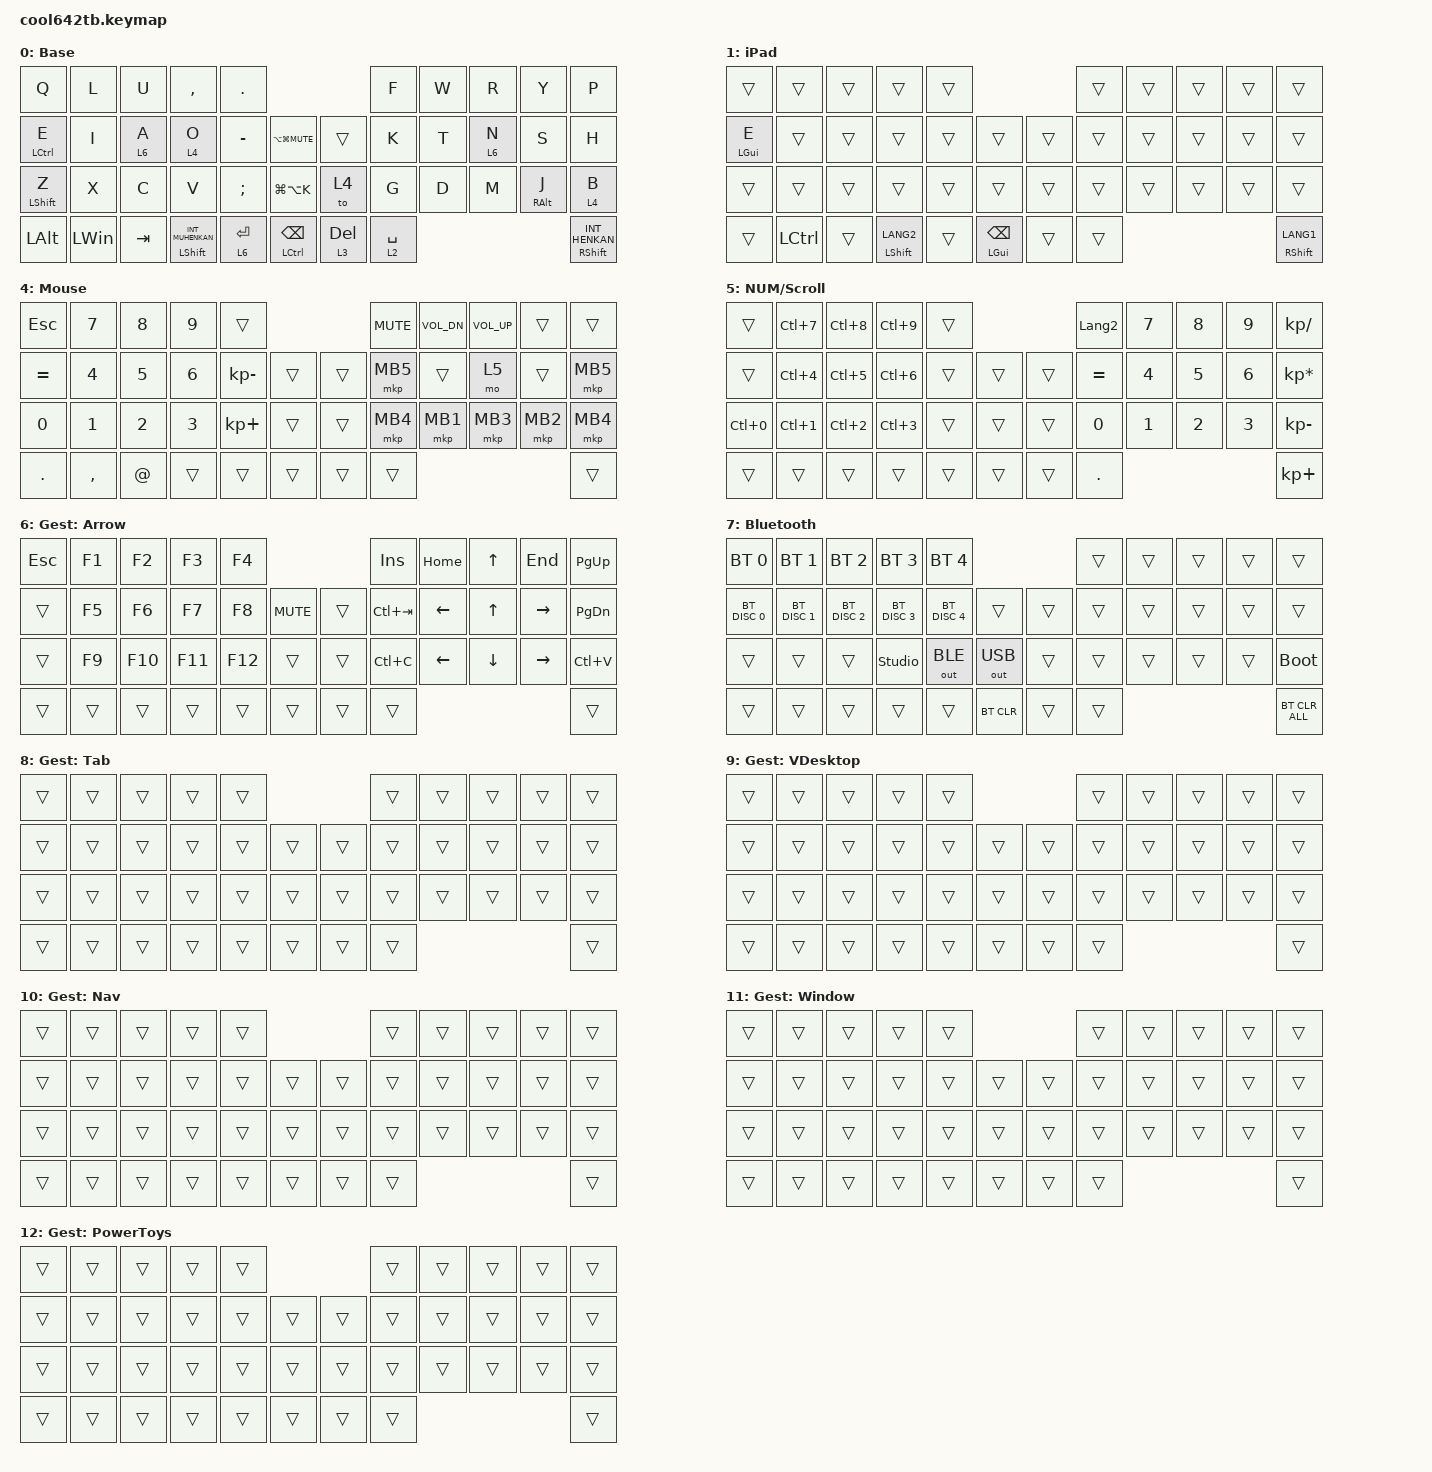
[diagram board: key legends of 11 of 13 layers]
#include <input/processors.dtsi>
#include <dt-bindings/zmk/input_transform.h>
#include <zephyr/dt-bindings/input/input-event-codes.h>

/* ── 1クリック = 1ノッチになる SCRL_VAL ──
 * &msc は押している間 trigger_period_ms (既定 16ms) ごとに
 *     move = SCRL_VAL * trigger_period_ms / 1000
 * を出力する。スムーススクロール有効時はホストが 1カウント = 1/16 ノッチと
 * 解釈するので 1000 * 0.016 = 16 カウント → 1ノッチ/クリックになる。
 * エンコーダ出力にはさらに mscbase×msclyr が掛かる (Studio で変更可)。 */

#undef ZMK_POINTING_DEFAULT_SCRL_VAL

#define ZMK_POINTING_DEFAULT_SCRL_VAL 1000

/* ランタイムマクロの &rmacro <slot> を提供。スロット番号は Studio で
 * マクロを作成したときに割り当てられる。 */

#include <behaviors/runtime_macro.dtsi>

/* &mg_set N を提供。押している間だけ RPC 側のセットが有効になる。
 * ただし Studio からは割り当てられないので、下の mg_set_0/1/2 を使う。 */

#include <mouse-gesture-rpc.dtsi>
#include <behaviors.dtsi>
#include <dt-bindings/zmk/bt.h>
#include <dt-bindings/zmk/keys.h>
#include <dt-bindings/zmk/outputs.h>
#include <dt-bindings/zmk/pointing.h>
#include "gestures.dtsi"

/* DYA Studio 用の「セット番号固定」ジェスチャーキー。
 *
 * Studio はパラメータ付きのカスタム behavior を保持できないため、汎用の
 * &mg_set N は Studio の一覧から割り当てられない。モジュール側は対策として
 * パラメータ無しの compatible "zmk,behavior-mg-set-fixed" を用意しているが、
 * ノード自体は定義していないので自前で作る。
 *
 * セット番号はノード名の末尾1文字から決まる。よってノード名は必ず
 * _0 / _1 / _2 で終わらせること。判定が '0'..'2' 固定なので3セットが上限。 */

/ {
    behaviors {
        mg_set_0: behavior_mg_set_0 {
            compatible = "zmk,behavior-mg-set-fixed";
            #binding-cells = <0>;
            display-name = "Mouse Gesture Key 0";
        };

        mg_set_1: behavior_mg_set_1 {
            compatible = "zmk,behavior-mg-set-fixed";
            #binding-cells = <0>;
            display-name = "Mouse Gesture Key 1";
        };

        mg_set_2: behavior_mg_set_2 {
            compatible = "zmk,behavior-mg-set-fixed";
            #binding-cells = <0>;
            display-name = "Mouse Gesture Key 2";
        };
    };
};

&mt {
    flavor = "tap-preferred";
    quick-tap-ms = <300>;
    require-prior-idle-ms = <125>;
    tapping-term-ms = <180>;
};

&lt {
    quick-tap-ms = <300>;
    flavor = "tap-preferred";
    require-prior-idle-ms = <125>;
    tapping-term-ms = <180>;
};

/* &msc (エンコーダのスクロール出力) の加速ランプを無効化。
 * 無いと ZMK 既定 (time-to-max-speed-ms = 300) が効き、1クリックでは
 * 立ち上がりの端数しか出ない。0 にすると1クリック分の値が即出る。 */

&msc {
    delay-ms = <0>;
    time-to-max-speed-ms = <0>;
    acceleration-exponent = <0>;
};

/ {
    input_processors {
        /* エンコーダ (&msc) 用ランタイムスケーラ2段。Studioから倍率・対象レイヤーを
         * 変えられる。実効 = mscbase × msclyr。
         * labelは7文字以内にすること (NAME_MAX_LEN=8、NUL込みで8に収める)。
         * x/y-codesは両方必須・同要素数 (上流bindingの制約)。反転なし。 */

        mscbase: mscbase {
            compatible = "zmk,input-processor-runtime";
            processor-label = "mscbase";
            #input-processor-cells = <0>;
            type = <INPUT_EV_REL>;
            x-codes = <INPUT_REL_HWHEEL>;
            y-codes = <INPUT_REL_WHEEL>;
            track-remainders;
            scale-multiplier = <1>;
            scale-divisor = <1>;
            active-layers = <0>; // 全レイヤー (0=全部)。ベース感度はここ
        };

        msclyr: msclyr {
            compatible = "zmk,input-processor-runtime";
            processor-label = "msclyr";
            #input-processor-cells = <0>;
            type = <INPUT_EV_REL>;
            x-codes = <INPUT_REL_HWHEEL>;
            y-codes = <INPUT_REL_WHEEL>;
            track-remainders;
            scale-multiplier = <3>;
            scale-divisor = <1>;
            active-layers = <8>; // SYM2のみ (BIT(3))。レイヤー別倍率はここ
        };
    };

    combos {
        compatible = "zmk,combos";

        comb1 {
            bindings = <&kp TAB>;
            key-positions = <11 10>;
        };

        comb2 {
            bindings = <&kp ESCAPE>;
            key-positions = <0 1>;
        };

        comb3 {
            bindings = <&kp CAPSLOCK>;
            key-positions = <22 23>;
        };

        comb4 {
            bindings = <&kp BACKSPACE>;
            key-positions = <9 8>;
        };

        JP {
            bindings = <&kp LANGUAGE_2>;
            key-positions = <13 12>;
        };

        EN {
            bindings = <&kp LANGUAGE_1>;
            key-positions = <18 19>;
        };

        BT {
            bindings = <&mo 7>;
            key-positions = <31 30>;
        };

        Layer_4 {
            bindings = <&mo 5>;
            key-positions = <31 32>;
        };

        Soft-Off {
            bindings = <&soft_off>;
            key-positions = <17 18 12 13 37 40>;
        };
    };

    macros {
        to_layer_0: to_layer_0 {
            compatible = "zmk,behavior-macro-one-param";
            #binding-cells = <1>;
            bindings = <&to 0 &macro_param_1to1 &kp MACRO_PLACEHOLDER>;
            label = "TO_LAYER_0";
        };

        P1: PW_1 {
            compatible = "zmk,behavior-macro";
            #binding-cells = <0>;
            bindings = <&kp LS(Y) &kp U &kp S &kp H &kp I &kp N1 &kp N9 &kp N9 &kp N1 &kp N0 &kp N3 &kp N0 &kp N6>;
            label = "PW_1";
        };

        BrowsToExplore: BrowsToExplore {
            compatible = "zmk,behavior-macro";
            #binding-cells = <0>;
            bindings = <&kp LS(LA(B)) &kp ENTER &kp LG(NUMBER_1)>;
            label = "BROWSTOEXPLORE";
        };

        /* ズームイン用マクロ: Ctrlを押しながらスクロールUP */

        zoom_in_macro: zoom_in_macro {
            compatible = "zmk,behavior-macro";
            #binding-cells = <0>;
            bindings =
                <&macro_press>,
                <&kp LCTRL>,
                <&macro_tap>,
                <&msc SCRL_UP>,
                <&macro_release>,
                <&kp LCTRL>;
        };

        /* ズームアウト用マクロ: Ctrlを押しながらスクロールDOWN */

        zoom_out_macro: zoom_out_macro {
            compatible = "zmk,behavior-macro";
            #binding-cells = <0>;
            bindings =
                <&macro_press>,
                <&kp LCTRL>,
                <&macro_tap>,
                <&msc SCRL_DOWN>,
                <&macro_release>,
                <&kp LCTRL>;
        };
    };

    behaviors {
        lt_to_layer_0: lt_to_layer_0 {
            compatible = "zmk,behavior-hold-tap";
            label = "LAYER_TAP_TO_0";
            bindings = <&mo>, <&to_layer_0>;

            #binding-cells = <2>;
            tapping-term-ms = <180>;
        };

        scroll_up_down: mouse_wheel_up_down {
            compatible = "zmk,behavior-runtime-sensor-rotate";
            #sensor-binding-cells = <0>;

            /* &msc は押下時には何も出さず trigger_period_ms (16ms) 後の
             * 最初のティックで初めて出力する。tap-ms を 16 にすると
             * 「ティック」と「離してキャンセル」が同時になり、クリックが
             * 丸ごと無視されることがある。24 なら必ず 1ティックだけ出る
             * (次のティックは 32ms なので 2回出ることもない)。
             * 向きは private/v0.3 の static 定義 (CW=UP) と同一。 */

            tap-ms = <24>;
            cw-binding = <&msc SCRL_UP>;
            ccw-binding = <&msc SCRL_DOWN>;
        };

        scroll_right_left: mouse_wheel_right_left {
            compatible = "zmk,behavior-runtime-sensor-rotate";
            #sensor-binding-cells = <0>;

            /* 向きは private/v0.3 と同一 (CW=LEFT)。 */

            tap-ms = <24>;
            cw-binding = <&msc SCRL_LEFT>;
            ccw-binding = <&msc SCRL_RIGHT>;
        };

        rsr_vol: rsr_vol {
            compatible = "zmk,behavior-runtime-sensor-rotate";
            #sensor-binding-cells = <0>;
            tap-ms = <5>; // 音量調整用に短めに設定
            cw-binding = <&kp C_VOL_DN>;
            ccw-binding = <&kp C_VOL_UP>;
        };
    };

    keymap {
        compatible = "zmk,keymap";

        default_layer {
            display-name = "Base";
            bindings = <
&kp Q             &kp L         &kp U    &kp COMMA                    &kp PERIOD                                     &kp F        &kp W  &kp R    &kp Y            &kp P
&mt LCTRL E       &kp I         &lt 6 A  &lt 4 O                      &kp MINUS      &kp LA(LG(C_MUTE))   &trans     &kp K        &kp T  &lt 6 N  &kp S            &kp H
&mt LEFT_SHIFT Z  &kp X         &kp C    &kp V                        &kp SEMICOLON  &kp LG(LA(K))        &to 4      &kp G        &kp D  &kp M    &mt RIGHT_ALT J  &lt 4 B
&kp LEFT_ALT      &kp LEFT_WIN  &kp TAB  &mt LEFT_SHIFT INT_MUHENKAN  &lt 6 ENTER    &mt LCTRL BACKSPACE  &lt 3 DEL  &lt 2 SPACE                                   &mt RIGHT_SHIFT INT_HENKAN
            >;

            sensor-bindings = <&scroll_up_down>;
        };

        /* iPad / iOS 用ベースレイヤー。
         *
         * zmk-feature-default-layer が OS 判定に応じて常時 ON にする。
         * レイヤー0を落とさず上に重ねる作りなので、Windows との差分だけを書き、
         * 残りは &trans でレイヤー0に落とす。
         *
         * 置き場所は index 1 でなければいけない。ZMK は有効なレイヤーを
         * 高い index から見るので、末尾に置くと機能レイヤーを
         * すべて上書きしてしまう。
         *
         * sensor-bindings は書かない。書かないレイヤーはエンコーダの探索で
         * 読み飛ばされ、レイヤー0の &scroll_up_down に落ちる。 */

        iPad {
            display-name = "iPad";
            bindings = <
&trans      &trans     &trans  &trans                &trans                                  &trans  &trans  &trans  &trans  &trans
&mt LGUI E  &trans     &trans  &trans                &trans  &trans                  &trans  &trans  &trans  &trans  &trans  &trans
&trans      &trans     &trans  &trans                &trans  &trans                  &trans  &trans  &trans  &trans  &trans  &trans
&trans      &kp LCTRL  &trans  &mt LEFT_SHIFT LANG2  &trans  &mt LEFT_GUI BACKSPACE  &trans  &trans                          &mt RIGHT_SHIFT LANG1
            >;
        };

        NUM,SYM1 {
            display-name = "NUM/SYM1";
            bindings = <
&kp N1                    &kp N2                    &kp N3           &kp N4                     &kp N5                                   &kp N6         &kp N7                &kp N8             &kp N9                &kp N0
&kp EQUAL                 &kp LEFT_BRACKET          &kp SLASH        &kp MINUS                  &kp LS(INTERNATIONAL_1)  &none   &none   &kp SEMICOLON  &kp SQT               &kp RIGHT_BRACKET  &kp BACKSLASH         &kp INT_YEN
&kp LC(LA(LC(NUMBER_2)))  &kp LC(LS(LA(NUMBER_6)))  &kp PRINTSCREEN  &kp LS(LG(S))              &kp LA(PRINTSCREEN)      &none   &none   &kp CAPSLOCK   &kp LS(LC(NUMBER_2))  &kp LS(LC(I))      &kp LS(LC(NUMBER_1))  &kp SCROLLLOCK
&trans                    &trans                    &trans           &mt LEFT_SHIFT LANGUAGE_1  &trans                   &trans  &trans  &trans                                                                        &trans
            >;

            sensor-bindings = <&scroll_right_left>;
        };

        SYM2 {
            display-name = "SYM2";
            bindings = <
&kp LS(NUMBER_1)   &kp LS(NUMBER_2)    &kp LS(NUMBER_3)  &kp LS(NUMBER_4)           &kp LS(N5)                               &kp LS(NUMBER_6)        &kp LS(N7)               &kp LS(N8)             &kp LS(N9)                  &kp LS(NUMBER_0)
&kp LS(EQUAL)      &kp LS(LEFT_BRACE)  &kp QUESTION      &kp LS(UNDERSCORE)         &kp LS(INTERNATIONAL_1)  &trans  &trans  &kp LS(SEMICOLON)       &kp LS(SQT)              &kp LS(RIGHT_BRACKET)  &kp LS(BACKSLASH)           &kp LS(INT3)
&kp LS(LA(MINUS))  &trans              &trans            &BrowsToExplore            &P1                      &trans  &trans  &kp LC(LG(LEFT_ARROW))  &kp LC(LG(RIGHT_ARROW))  &kp LC(LG(LA(D)))      &kp LA(LC(LG(LEFT_ARROW)))  &kp LA(LC(LG(RIGHT_ARROW)))
&trans             &trans              &trans            &mt LEFT_SHIFT LANGUAGE_2  &trans                   &trans  &trans  &trans                                                                                              &kp LC(LG(F4))
            >;

            sensor-bindings = <&scroll_up_down>;
        };

        MOUSE {
            display-name = "Mouse";
            bindings = <
&kp ESCAPE  &kp N7        &kp N8        &kp N9        &trans                        &kp C_MUTE  &kp C_VOL_DN  &kp C_VOLUME_UP  &trans    &trans
&kp EQUAL   &kp NUMBER_4  &kp N5        &kp NUMBER_6  &kp KP_MINUS  &trans  &trans  &mkp MB5    &trans        &mo 5            &trans    &mkp MB5
&kp N0      &kp NUMBER_1  &kp NUMBER_2  &kp NUMBER_3  &kp KP_PLUS   &trans  &trans  &mkp MB4    &mkp MB1      &mkp MB3         &mkp MB2  &mkp MB4
&kp DOT     &kp COMMA     &kp AT        &trans        &trans        &trans  &trans  &trans                                               &trans
            >;

            sensor-bindings = <&rsr_vol>;
        };

        NUM-SCROLL {
            display-name = "NUM/Scroll";
            bindings = <
&trans            &kp LC(NUMBER_7)  &kp LC(NUMBER_8)  &kp LC(NUMBER_9)  &trans                  &kp LANGUAGE_2  &kp NUMBER_7  &kp NUMBER_8  &kp NUMBER_9  &kp KP_SLASH
&trans            &kp LC(NUMBER_4)  &kp LC(NUMBER_5)  &kp LC(NUMBER_6)  &trans  &trans  &trans  &kp EQUAL       &kp NUMBER_4  &kp NUMBER_5  &kp NUMBER_6  &kp KP_ASTERISK
&kp LC(NUMBER_0)  &kp LC(NUMBER_1)  &kp LC(NUMBER_2)  &kp LC(NUMBER_3)  &trans  &trans  &trans  &kp NUMBER_0    &kp NUMBER_1  &kp NUMBER_2  &kp NUMBER_3  &kp KP_MINUS
&trans            &trans            &trans            &trans            &trans  &trans  &trans  &kp DOT                                                   &kp KP_PLUS
            >;

            sensor-bindings = <&scroll_up_down>;
        };

        gest_arrow {
            display-name = "Gest: Arrow";
            bindings = <
&kp ESC  &kp F1  &kp F2   &kp F3   &kp F4                       &kp INSERT   &kp HOME        &kp UP_ARROW  &kp END    &kp PAGE_UP
&trans   &kp F5  &kp F6   &kp F7   &kp F8   &kp C_MUTE  &trans  &kp LC(TAB)  &kp LEFT_ARROW  &kp UP_ARROW  &kp RIGHT  &kp PAGE_DOWN
&trans   &kp F9  &kp F10  &kp F11  &kp F12  &trans      &trans  &kp LC(C)    &kp LEFT        &kp DOWN      &kp RIGHT  &kp LC(V)
&trans   &trans  &trans   &trans   &trans   &trans      &trans  &trans                                                &trans
            >;

            sensor-bindings = <&scroll_right_left>;
        };

        bluetooth {
            display-name = "Bluetooth";
            bindings = <
&bt BT_SEL 0   &bt BT_SEL 1   &bt BT_SEL 2   &bt BT_SEL 3    &bt BT_SEL 4                         &trans  &trans  &trans  &trans  &trans
&bt BT_DISC 0  &bt BT_DISC 1  &bt BT_DISC 2  &bt BT_DISC 3   &bt BT_DISC 4  &trans        &trans  &trans  &trans  &trans  &trans  &trans
&trans         &trans         &trans         &studio_unlock  &out OUT_BLE   &out OUT_USB  &trans  &trans  &trans  &trans  &trans  &bootloader
&trans         &trans         &trans         &trans          &trans         &bt BT_CLR    &trans  &trans                          &bt BT_CLR_ALL
            >;

            sensor-bindings = <&scroll_up_down>;
        };

        gest_tab {
            display-name = "Gest: Tab";
            bindings = <
&trans  &trans  &trans  &trans  &trans                  &trans  &trans  &trans  &trans  &trans
&trans  &trans  &trans  &trans  &trans  &trans  &trans  &trans  &trans  &trans  &trans  &trans
&trans  &trans  &trans  &trans  &trans  &trans  &trans  &trans  &trans  &trans  &trans  &trans
&trans  &trans  &trans  &trans  &trans  &trans  &trans  &trans                          &trans
            >;
        };

        gest_vdesktop {
            display-name = "Gest: VDesktop";
            bindings = <
&trans  &trans  &trans  &trans  &trans                  &trans  &trans  &trans  &trans  &trans
&trans  &trans  &trans  &trans  &trans  &trans  &trans  &trans  &trans  &trans  &trans  &trans
&trans  &trans  &trans  &trans  &trans  &trans  &trans  &trans  &trans  &trans  &trans  &trans
&trans  &trans  &trans  &trans  &trans  &trans  &trans  &trans                          &trans
            >;
        };

        gest_nav {
            display-name = "Gest: Nav";
            bindings = <
&trans  &trans  &trans  &trans  &trans                  &trans  &trans  &trans  &trans  &trans
&trans  &trans  &trans  &trans  &trans  &trans  &trans  &trans  &trans  &trans  &trans  &trans
&trans  &trans  &trans  &trans  &trans  &trans  &trans  &trans  &trans  &trans  &trans  &trans
&trans  &trans  &trans  &trans  &trans  &trans  &trans  &trans                          &trans
            >;
        };

        gest_window {
            display-name = "Gest: Window";
            bindings = <
&trans  &trans  &trans  &trans  &trans                  &trans  &trans  &trans  &trans  &trans
&trans  &trans  &trans  &trans  &trans  &trans  &trans  &trans  &trans  &trans  &trans  &trans
&trans  &trans  &trans  &trans  &trans  &trans  &trans  &trans  &trans  &trans  &trans  &trans
&trans  &trans  &trans  &trans  &trans  &trans  &trans  &trans                          &trans
            >;
        };

        gest_powertoys {
            display-name = "Gest: PowerToys";
            bindings = <
&trans  &trans  &trans  &trans  &trans                  &trans  &trans  &trans  &trans  &trans
&trans  &trans  &trans  &trans  &trans  &trans  &trans  &trans  &trans  &trans  &trans  &trans
&trans  &trans  &trans  &trans  &trans  &trans  &trans  &trans  &trans  &trans  &trans  &trans
&trans  &trans  &trans  &trans  &trans  &trans  &trans  &trans                          &trans
            >;
        };
    };
};

/* エンコーダ (&msc) 出力チェーン。倍率と対象レイヤーは
 * mscbase (ベース感度・全層) と msclyr (レイヤー別倍率) で持ち、
 * Studioから変えられる。既定は mscbase 1倍・msclyr SYM2のみ3倍。
 * 2段ともactiveな層では乗算になるため、マスクは排他に保つこと。 */

&msc_input_listener { input-processors = <&mscbase &msclyr>; };
